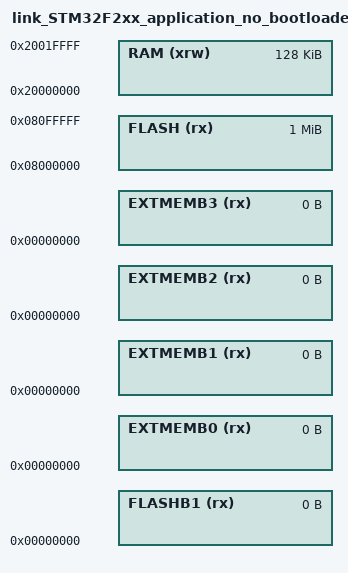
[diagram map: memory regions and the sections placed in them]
/**
 ******************************************************************************
 *
 * @file       link_STM32F2xx_bootloader.ld   
 * @author     The OpenPilot Team, http://www.openpilot.org Copyright (C) 2009.   
 * @brief      PiOS linker for the OpenPilot board
 * @see        The GNU Public License (GPL) Version 3
 *
 *****************************************************************************/
/* 
 * This program is free software; you can redistribute it and/or modify 
 * it under the terms of the GNU General Public License as published by 
 * the Free Software Foundation; either version 3 of the License, or 
 * (at your option) any later version.
 * 
 * This program is distributed in the hope that it will be useful, but 
 * WITHOUT ANY WARRANTY; without even the implied warranty of MERCHANTABILITY 
 * or FITNESS FOR A PARTICULAR PURPOSE. See the GNU General Public License 
 * for more details.
 * 
 * You should have received a copy of the GNU General Public License along 
 * with this program; if not, write to the Free Software Foundation, Inc., 
 * 59 Temple Place, Suite 330, Boston, MA 02111-1307 USA
 */

/* Memory Spaces Definitions */
MEMORY
{
  RAM (xrw) :     ORIGIN = 0x20000000, LENGTH = 128K
  FLASH (rx) :    ORIGIN = 0x08000000, LENGTH = 1024K
  FLASHB1 (rx) :  ORIGIN = 0x00000000, LENGTH = 0
  EXTMEMB0 (rx) : ORIGIN = 0x00000000, LENGTH = 0
  EXTMEMB1 (rx) : ORIGIN = 0x00000000, LENGTH = 0
  EXTMEMB2 (rx) : ORIGIN = 0x00000000, LENGTH = 0
  EXTMEMB3 (rx) : ORIGIN = 0x00000000, LENGTH = 0
}

INCLUDE link_STM32F2xx_common.ld
